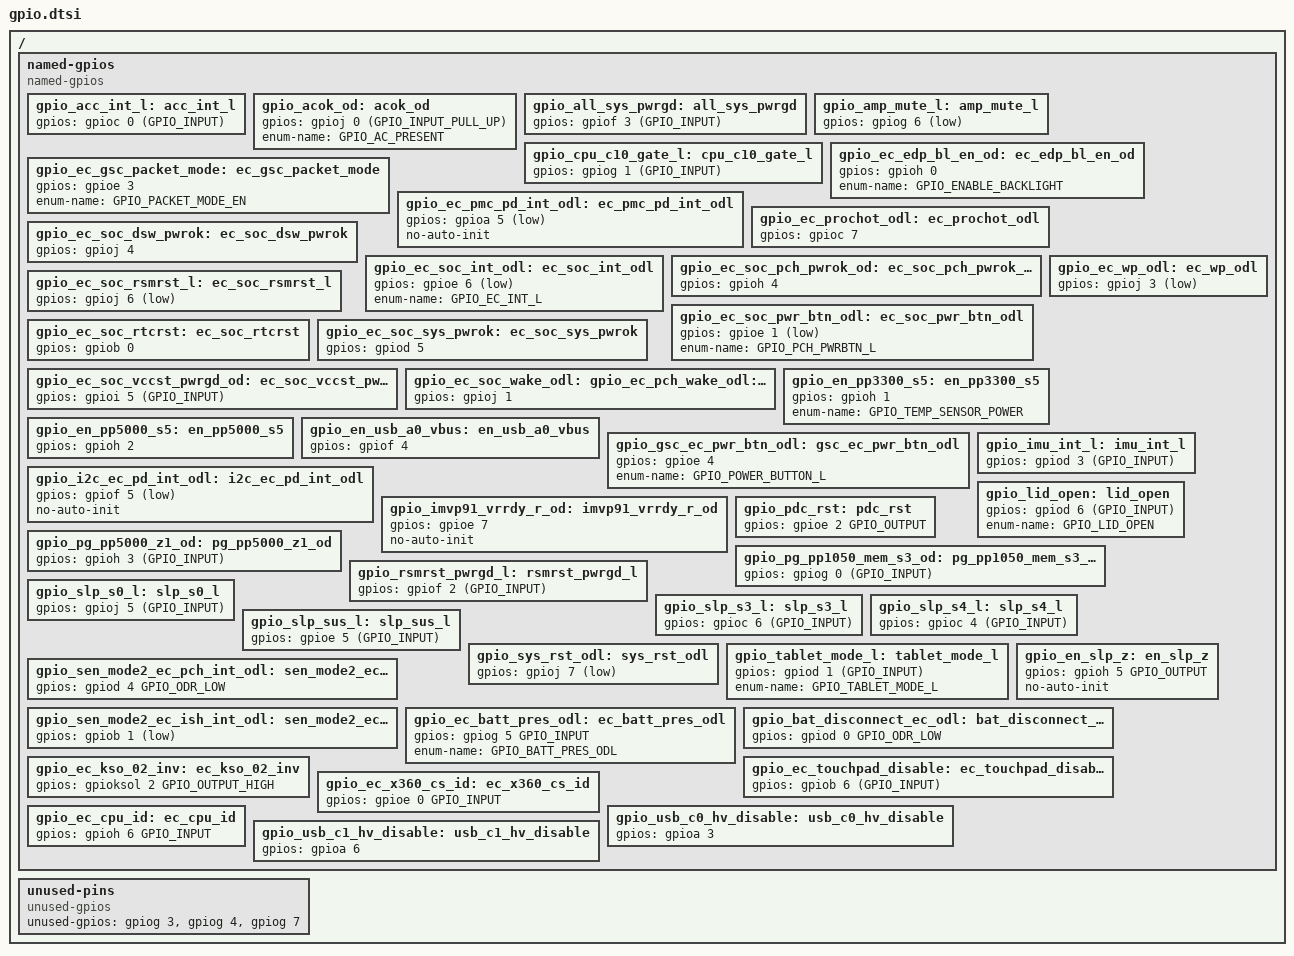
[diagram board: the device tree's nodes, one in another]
/* Copyright 2025 The ChromiumOS Authors
 * Use of this source code is governed by a BSD-style license that can be
 * found in the LICENSE file.
 */

/ {

	named-gpios {
		compatible = "named-gpios";

		gpio_acc_int_l: acc_int_l {
			gpios = <&gpioc 0 (GPIO_INPUT)>;
		};
		gpio_acok_od: acok_od {
			gpios = <&gpioj 0 (GPIO_INPUT_PULL_UP)>;
			enum-name = "GPIO_AC_PRESENT";
		};
		gpio_all_sys_pwrgd: all_sys_pwrgd {
			gpios = <&gpiof 3 (GPIO_INPUT)>;
		};
		gpio_amp_mute_l: amp_mute_l {
			gpios = <&gpiog 6 (GPIO_OUTPUT | GPIO_ACTIVE_LOW | GPIO_OUTPUT_INIT_HIGH)>;
		};
		gpio_cpu_c10_gate_l: cpu_c10_gate_l {
			gpios = <&gpiog 1 (GPIO_INPUT)>;
		};
		gpio_ec_edp_bl_en_od: ec_edp_bl_en_od {
			gpios = <&gpioh 0 (GPIO_OUTPUT | GPIO_OPEN_DRAIN | GPIO_ACTIVE_HIGH | GPIO_OUTPUT_INIT_LOW)>;
			enum-name = "GPIO_ENABLE_BACKLIGHT";
		};
		gpio_ec_gsc_packet_mode: ec_gsc_packet_mode {
			gpios = <&gpioe 3 (GPIO_OUTPUT | GPIO_ACTIVE_HIGH | GPIO_OUTPUT_INIT_LOW)>;
			enum-name = "GPIO_PACKET_MODE_EN";
		};
		gpio_ec_pmc_pd_int_odl: ec_pmc_pd_int_odl {
			gpios = <&gpioa 5 (GPIO_OUTPUT | GPIO_OPEN_DRAIN | GPIO_ACTIVE_LOW)>;
		};
		gpio_ec_prochot_odl: ec_prochot_odl {
			gpios = <&gpioc 7 (GPIO_OUTPUT | GPIO_ACTIVE_HIGH | GPIO_OUTPUT_INIT_LOW)>;
		};
		gpio_ec_soc_dsw_pwrok: ec_soc_dsw_pwrok {
			gpios = <&gpioj 4 (GPIO_OUTPUT | GPIO_ACTIVE_HIGH | GPIO_OUTPUT_INIT_LOW)>;
		};
		gpio_ec_soc_int_odl: ec_soc_int_odl {
			gpios = <&gpioe 6 (GPIO_OUTPUT | GPIO_OPEN_DRAIN | GPIO_ACTIVE_LOW | GPIO_OUTPUT_INIT_HIGH)>;
			enum-name = "GPIO_EC_INT_L";
		};
		gpio_ec_soc_pch_pwrok_od: ec_soc_pch_pwrok_od {
			gpios = <&gpioh 4 (GPIO_OUTPUT | GPIO_OPEN_DRAIN | GPIO_ACTIVE_HIGH | GPIO_OUTPUT_INIT_HIGH)>;
		};
		gpio_ec_soc_pwr_btn_odl: ec_soc_pwr_btn_odl {
			gpios = <&gpioe 1 (GPIO_OUTPUT | GPIO_OPEN_DRAIN | GPIO_ACTIVE_LOW | GPIO_OUTPUT_INIT_HIGH)>;
			enum-name = "GPIO_PCH_PWRBTN_L";
		};
		gpio_ec_soc_rsmrst_l: ec_soc_rsmrst_l {
			gpios = <&gpioj 6 (GPIO_OUTPUT | GPIO_ACTIVE_LOW | GPIO_OUTPUT_INIT_HIGH)>;
		};
		gpio_ec_soc_rtcrst: ec_soc_rtcrst {
			gpios = <&gpiob 0 (GPIO_OUTPUT | GPIO_ACTIVE_HIGH | GPIO_OUTPUT_INIT_LOW)>;
		};
		gpio_ec_soc_sys_pwrok: ec_soc_sys_pwrok {
			gpios = <&gpiod 5 (GPIO_OUTPUT | GPIO_ACTIVE_HIGH | GPIO_OUTPUT_INIT_LOW)>;
		};
		gpio_ec_soc_vccst_pwrgd_od: ec_soc_vccst_pwrgd_od {
			gpios = <&gpioi 5 (GPIO_INPUT)>;
		};
		gpio_ec_soc_wake_odl: ec_soc_wake_odl {
			gpios = <&gpioj 1 (GPIO_OUTPUT | GPIO_OPEN_DRAIN | GPIO_OUTPUT_INIT_LOW)>;
		};
		gpio_ec_wp_odl: ec_wp_odl {
			gpios = <&gpioj 3 (GPIO_INPUT | GPIO_ACTIVE_LOW)>;
		};
		gpio_en_pp3300_s5: en_pp3300_s5 {
			gpios = <&gpioh 1 (GPIO_OUTPUT | GPIO_ACTIVE_HIGH | GPIO_OUTPUT_INIT_LOW)>;
			enum-name = "GPIO_TEMP_SENSOR_POWER";
		};
		gpio_en_pp5000_s5: en_pp5000_s5 {
			gpios = <&gpioh 2 (GPIO_OUTPUT | GPIO_ACTIVE_HIGH | GPIO_OUTPUT_INIT_LOW)>;
		};
		gpio_en_usb_a0_vbus: en_usb_a0_vbus {
			gpios = <&gpiof 4 (GPIO_OUTPUT | GPIO_ACTIVE_HIGH | GPIO_OUTPUT_INIT_LOW)>;
		};
		gpio_gsc_ec_pwr_btn_odl: gsc_ec_pwr_btn_odl {
			gpios = <&gpioe 4 (GPIO_INPUT | GPIO_PULL_UP)>;
			enum-name = "GPIO_POWER_BUTTON_L";
		};
		gpio_i2c_ec_pd_int_odl: i2c_ec_pd_int_odl {
			gpios = <&gpiof 5 (GPIO_INPUT | GPIO_ACTIVE_LOW)>;
		};
		gpio_imu_int_l: imu_int_l {
			gpios = <&gpiod 3 (GPIO_INPUT)>;
		};
		gpio_imvp91_vrrdy_r_od: imvp91_vrrdy_r_od {
			gpios = <&gpioe 7 (GPIO_OUTPUT | GPIO_OPEN_DRAIN | GPIO_ACTIVE_HIGH | GPIO_OUTPUT_INIT_LOW)>;
		};
		gpio_lid_open: lid_open {
			gpios = <&gpiod 6 (GPIO_INPUT)>;
			enum-name = "GPIO_LID_OPEN";
		};
		gpio_pdc_rst: pdc_rst {
			gpios = <&gpioe 2 GPIO_OUTPUT>;
		};
		gpio_pg_pp1050_mem_s3_od: pg_pp1050_mem_s3_od {
			gpios = <&gpiog 0 (GPIO_INPUT)>;
		};
		gpio_pg_pp5000_z1_od: pg_pp5000_z1_od {
			gpios = <&gpioh 3 (GPIO_INPUT)>;
		};
		gpio_rsmrst_pwrgd_l: rsmrst_pwrgd_l {
			gpios = <&gpiof 2 (GPIO_INPUT)>;
		};
		gpio_slp_s0_l: slp_s0_l {
			gpios = <&gpioj 5 (GPIO_INPUT)>;
		};
		gpio_slp_s3_l: slp_s3_l {
			gpios = <&gpioc 6 (GPIO_INPUT)>;
		};
		gpio_slp_s4_l: slp_s4_l {
			gpios = <&gpioc 4 (GPIO_INPUT)>;
		};
		gpio_slp_sus_l: slp_sus_l {
			gpios = <&gpioe 5 (GPIO_INPUT)>;
		};
		gpio_sys_rst_odl: sys_rst_odl {
			gpios = <&gpioj 7 (GPIO_OUTPUT | GPIO_OPEN_DRAIN | GPIO_ACTIVE_LOW)>;
		};
		gpio_tablet_mode_l: tablet_mode_l {
			gpios = <&gpiod 1 (GPIO_INPUT)>;
			enum-name = "GPIO_TABLET_MODE_L";
		};
		gpio_sen_mode2_ec_pch_int_odl: sen_mode2_ec_pch_int_odl {
			gpios = <&gpiod 4 GPIO_ODR_LOW>;
		};
		gpio_sen_mode2_ec_ish_int_odl: sen_mode2_ec_ish_int_odl {
			gpios = <&gpiob 1 (GPIO_ACTIVE_LOW)>;
		};
		gpio_en_slp_z: en_slp_z {
			gpios = <&gpioh 5 GPIO_OUTPUT>;
			no-auto-init;
		};
		gpio_ec_batt_pres_odl: ec_batt_pres_odl {
			gpios = <&gpiog 5 GPIO_INPUT>;
			enum-name = "GPIO_BATT_PRES_ODL";
		};
		gpio_bat_disconnect_ec_odl: bat_disconnect_ec_odl {
			gpios = <&gpiod 0 GPIO_ODR_LOW>;
		};
		gpio_ec_kso_02_inv: ec_kso_02_inv {
			gpios = <&gpioksol 2 GPIO_OUTPUT_HIGH>;
		};
		gpio_ec_touchpad_disable: ec_touchpad_disable {
			gpios = <&gpiob 6 (GPIO_INPUT)>;
		};
		gpio_ec_x360_cs_id: ec_x360_cs_id {
			gpios = <&gpioe 0 GPIO_INPUT>;
		};
		gpio_ec_cpu_id: ec_cpu_id {
			gpios = <&gpioh 6 GPIO_INPUT>;
		};
		gpio_usb_c0_hv_disable: usb_c0_hv_disable {
			gpios = <&gpioa 3 (GPIO_OUTPUT | GPIO_ACTIVE_HIGH | GPIO_OUTPUT_INIT_LOW)>;
		};
		gpio_usb_c1_hv_disable: usb_c1_hv_disable {
			gpios = <&gpioa 6 (GPIO_OUTPUT | GPIO_ACTIVE_HIGH | GPIO_OUTPUT_INIT_LOW)>;
		};
	};
	unused-pins {
		compatible = "unused-gpios";

		unused-gpios =
			/* EC_GPG3 */
			<&gpiog 3 0>,
			/* EC_GPG4 */
			<&gpiog 4 0>,
			/* EC_GPG7 */
			<&gpiog 7 0>;
		};
};

/* The eSPI shim requires this GPIO nodelabel */
gpio_ec_pch_wake_odl: &gpio_ec_soc_wake_odl{
};

/* These GPIOS are initialized by the PDC driver */
&gpio_i2c_ec_pd_int_odl {
	no-auto-init;
};
&gpio_ec_pmc_pd_int_odl {
	no-auto-init;
};
&gpio_imvp91_vrrdy_r_od  {
	no-auto-init;
};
